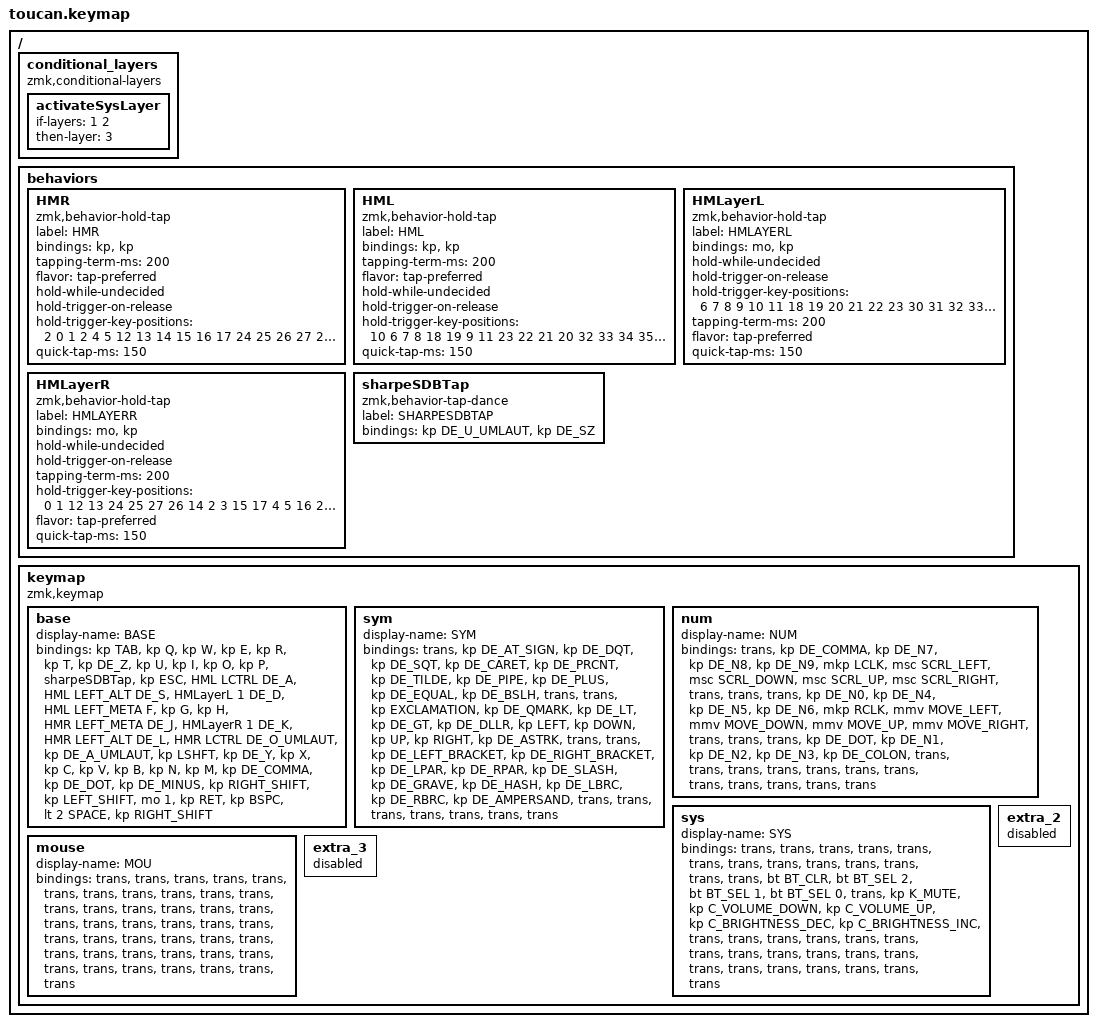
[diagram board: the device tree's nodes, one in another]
#include <behaviors.dtsi>
#include <dt-bindings/zmk/bt.h>
#include <dt-bindings/zmk/keys.h>
#include <dt-bindings/zmk/pointing.h>
#include "keys_de.h"

#define BASE 0
#define SYM  1
#define NUM  2
#define SYS  3

/ {
    conditional_layers {
        compatible = "zmk,conditional-layers";

        activateSysLayer {
            if-layers = <1 2>;
            then-layer = <3>;
        };
    };

    behaviors {
        HMR: HMR {
            compatible = "zmk,behavior-hold-tap";
            label = "HMR";
            bindings = <&kp>, <&kp>;

            #binding-cells = <2>;
            tapping-term-ms = <200>;
            flavor = "tap-preferred";
            hold-while-undecided;
            hold-trigger-on-release;
            hold-trigger-key-positions = <2 0 1 2 4 5 12 13 14 15 16 17 24 25 26 27 28 29 36 37 3 38>;
            quick-tap-ms = <150>;
        };

        HML: HML {
            compatible = "zmk,behavior-hold-tap";
            label = "HML";
            bindings = <&kp>, <&kp>;

            #binding-cells = <2>;
            tapping-term-ms = <200>;
            flavor = "tap-preferred";
            hold-while-undecided;
            hold-trigger-on-release;
            hold-trigger-key-positions = <10 6 7 8 18 19 9 11 23 22 21 20 32 33 34 35 31 30 40 41 39>;
            quick-tap-ms = <150>;
        };

        HMLayerL: HMLayerL {
            compatible = "zmk,behavior-hold-tap";
            label = "HMLAYERL";
            bindings = <&mo>, <&kp>;

            #binding-cells = <2>;
            hold-while-undecided;
            hold-trigger-on-release;
            hold-trigger-key-positions = <6 7 8 9 10 11 18 19 20 21 22 23 30 31 32 33 34 35 40 41 39>;
            tapping-term-ms = <200>;
            flavor = "tap-preferred";
            quick-tap-ms = <150>;
        };

        HMLayerR: HMLayerR {
            compatible = "zmk,behavior-hold-tap";
            label = "HMLAYERR";
            bindings = <&mo>, <&kp>;

            #binding-cells = <2>;
            hold-while-undecided;
            hold-trigger-on-release;
            tapping-term-ms = <200>;
            hold-trigger-key-positions = <0 1 12 13 24 25 27 26 14 2 3 15 17 4 5 16 28 29 36 37 38>;
            flavor = "tap-preferred";
            quick-tap-ms = <150>;
        };

        sharpeSDBTap: sharpeSDBTap {
            compatible = "zmk,behavior-tap-dance";
            label = "SHARPESDBTAP";
            #binding-cells = <0>;
            bindings = <&kp DE_U_UMLAUT>, <&kp DE_SZ>;
        };
    };

    keymap {
        compatible = "zmk,keymap";

        base {
            display-name = "BASE";
            bindings = <
&kp TAB  &kp Q  &kp W  &kp E  &kp R  &kp T  &kp DE_Z  &kp U  &kp I  &kp O  &kp P  &sharpeSDBTap  &kp ESC  &HML LCTRL DE_A  &HML LEFT_ALT DE_S  &HMLayerL 1 DE_D  &HML LEFT_META F  &kp G  &kp H  &HMR LEFT_META DE_J  &HMLayerR 1 DE_K  &HMR LEFT_ALT DE_L  &HMR LCTRL DE_O_UMLAUT  &kp DE_A_UMLAUT  &kp LSHFT  &kp DE_Y  &kp X  &kp C  &kp V  &kp B  &kp N  &kp M  &kp DE_COMMA  &kp DE_DOT  &kp DE_MINUS  &kp RIGHT_SHIFT  &kp LEFT_SHIFT  &mo 1  &kp RET  &kp BSPC  &lt 2 SPACE  &kp RIGHT_SHIFT
            >;
        };

        sym {
            display-name = "SYM";
            bindings = <
&trans  &kp DE_AT_SIGN  &kp DE_DQT  &kp DE_SQT  &kp DE_CARET  &kp DE_PRCNT  &kp DE_TILDE  &kp DE_PIPE  &kp DE_PLUS  &kp DE_EQUAL  &kp DE_BSLH  &trans  &trans  &kp EXCLAMATION  &kp DE_QMARK  &kp DE_LT  &kp DE_GT  &kp DE_DLLR  &kp LEFT  &kp DOWN  &kp UP  &kp RIGHT  &kp DE_ASTRK  &trans  &trans  &kp DE_LEFT_BRACKET  &kp DE_RIGHT_BRACKET  &kp DE_LPAR  &kp DE_RPAR  &kp DE_SLASH  &kp DE_GRAVE  &kp DE_HASH  &kp DE_LBRC  &kp DE_RBRC  &kp DE_AMPERSAND  &trans  &trans  &trans  &trans  &trans  &trans  &trans
            >;
        };

        num {
            display-name = "NUM";
            bindings = <
&trans  &kp DE_COMMA  &kp DE_N7  &kp DE_N8  &kp DE_N9  &mkp LCLK  &msc SCRL_LEFT  &msc SCRL_DOWN  &msc SCRL_UP  &msc SCRL_RIGHT  &trans  &trans  &trans  &kp DE_N0  &kp DE_N4  &kp DE_N5  &kp DE_N6  &mkp RCLK  &mmv MOVE_LEFT  &mmv MOVE_DOWN  &mmv MOVE_UP  &mmv MOVE_RIGHT  &trans  &trans  &trans  &kp DE_DOT  &kp DE_N1  &kp DE_N2  &kp DE_N3  &kp DE_COLON  &trans  &trans  &trans  &trans  &trans  &trans  &trans  &trans  &trans  &trans  &trans  &trans
            >;
        };

        sys {
            display-name = "SYS";
            bindings = <
&trans  &trans  &trans  &trans  &trans  &trans  &trans  &trans  &trans  &trans  &trans  &trans  &trans  &bt BT_CLR  &bt BT_SEL 2  &bt BT_SEL 1  &bt BT_SEL 0  &trans  &kp K_MUTE  &kp C_VOLUME_DOWN  &kp C_VOLUME_UP  &kp C_BRIGHTNESS_DEC  &kp C_BRIGHTNESS_INC  &trans  &trans  &trans  &trans  &trans  &trans  &trans  &trans  &trans  &trans  &trans  &trans  &trans  &trans  &trans  &trans  &trans  &trans  &trans
            >;
        };

        mouse {
            display-name = "MOU";
            bindings = <
&trans  &trans  &trans  &trans  &trans  &trans  &trans  &trans  &trans  &trans  &trans  &trans  &trans  &trans  &trans  &trans  &trans  &trans  &trans  &trans  &trans  &trans  &trans  &trans  &trans  &trans  &trans  &trans  &trans  &trans  &trans  &trans  &trans  &trans  &trans  &trans  &trans  &trans  &trans  &trans  &trans  &trans
            >;
        };

        extra_2 { status = "reserved"; };

        extra_3 { status = "reserved"; };
    };
};
